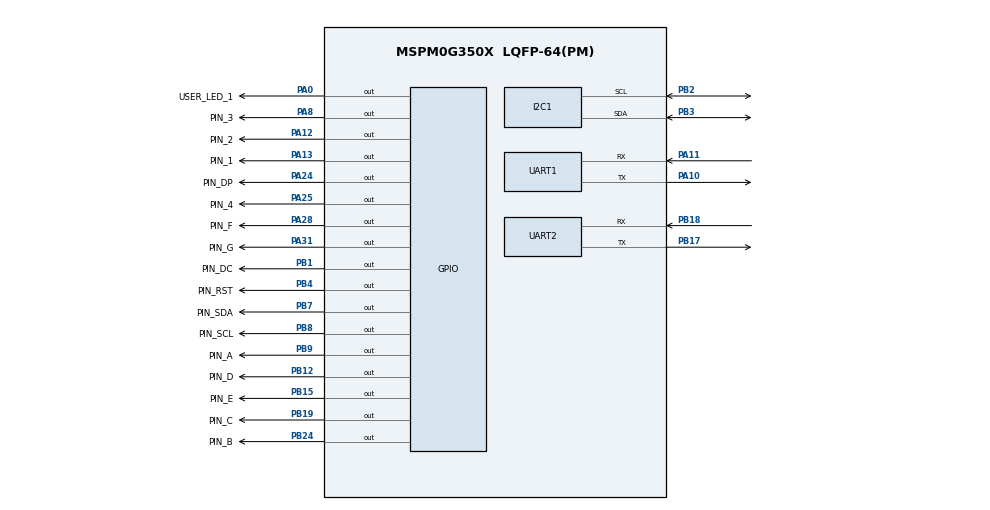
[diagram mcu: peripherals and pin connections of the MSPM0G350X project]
/**
 * @cliArgs --device "MSPM0G350X" --part "Default" --package "LQFP-64(PM)" --product "mspm0_sdk@2.05.01.00"
 * @versions {"tool":"1.24.0+4110"}
 */

/**
 * Import the modules used in this configuration.
 */
const GPIO  = scripting.addModule("/ti/driverlib/GPIO", {}, false);
const GPIO1 = GPIO.addInstance();
const GPIO2 = GPIO.addInstance();
const GPIO3 = GPIO.addInstance();
const I2C   = scripting.addModule("/ti/driverlib/I2C", {}, false);
const I2C1  = I2C.addInstance();
const UART  = scripting.addModule("/ti/driverlib/UART", {}, false);
const UART1 = UART.addInstance();
const UART2 = UART.addInstance();

/**
 * Write custom configuration values to the imported modules.
 */
GPIO1.$name                          = "GPIO_LEDS";
GPIO1.associatedPins.create(2);
GPIO1.associatedPins[0].$name        = "USER_LED_1";
GPIO1.associatedPins[0].assignedPort = "PORTA";
GPIO1.associatedPins[0].initialValue = "SET";
GPIO1.associatedPins[0].assignedPin  = "0";
GPIO1.associatedPins[0].pin.$assign  = "PA0";
GPIO1.associatedPins[1].$name        = "USER_TEST";
GPIO1.associatedPins[1].assignedPort = "PORTA";
GPIO1.associatedPins[1].assignedPin  = "15";
GPIO1.associatedPins[1].initialValue = "SET";

const Board           = scripting.addModule("/ti/driverlib/Board", {}, false);
Board.configureUnused = true;

GPIO2.$name                         = "GPIO_OLED";
GPIO2.associatedPins.create(4);
GPIO2.associatedPins[0].$name       = "PIN_SCL";
GPIO2.associatedPins[0].pin.$assign = "PB8";
GPIO2.associatedPins[1].$name       = "PIN_SDA";
GPIO2.associatedPins[1].pin.$assign = "PB7";
GPIO2.associatedPins[2].$name       = "PIN_RST";
GPIO2.associatedPins[2].pin.$assign = "PB4";
GPIO2.associatedPins[3].$name       = "PIN_DC";
GPIO2.associatedPins[3].pin.$assign = "PB1";

GPIO3.$name                          = "GPIO_GRP_0";
GPIO3.associatedPins.create(12);
GPIO3.associatedPins[0].$name        = "PIN_1";
GPIO3.associatedPins[0].pin.$assign  = "PA13";
GPIO3.associatedPins[1].$name        = "PIN_2";
GPIO3.associatedPins[1].pin.$assign  = "PA12";
GPIO3.associatedPins[2].$name        = "PIN_3";
GPIO3.associatedPins[2].pin.$assign  = "PA8";
GPIO3.associatedPins[3].$name        = "PIN_4";
GPIO3.associatedPins[3].pin.$assign  = "PA25";
GPIO3.associatedPins[4].$name        = "PIN_A";
GPIO3.associatedPins[4].pin.$assign  = "PB9";
GPIO3.associatedPins[5].$name        = "PIN_B";
GPIO3.associatedPins[5].pin.$assign  = "PB24";
GPIO3.associatedPins[6].$name        = "PIN_C";
GPIO3.associatedPins[6].pin.$assign  = "PB19";
GPIO3.associatedPins[7].$name        = "PIN_D";
GPIO3.associatedPins[7].pin.$assign  = "PB12";
GPIO3.associatedPins[8].$name        = "PIN_E";
GPIO3.associatedPins[8].pin.$assign  = "PB15";
GPIO3.associatedPins[9].$name        = "PIN_F";
GPIO3.associatedPins[9].pin.$assign  = "PA28";
GPIO3.associatedPins[10].$name       = "PIN_G";
GPIO3.associatedPins[10].pin.$assign = "PA31";
GPIO3.associatedPins[11].$name       = "PIN_DP";
GPIO3.associatedPins[11].pin.$assign = "PA24";

I2C1.basicControllerStandardBusSpeed   = "Fast";
I2C1.basicEnableController             = true;
I2C1.$name                             = "I2C_1";
I2C1.peripheral.$assign                = "I2C1";
I2C1.peripheral.sdaPin.$assign         = "PB3";
I2C1.peripheral.sclPin.$assign         = "PB2";
I2C1.sdaPinConfig.hideOutputInversion  = scripting.forceWrite(false);
I2C1.sdaPinConfig.onlyInternalResistor = scripting.forceWrite(false);
I2C1.sdaPinConfig.passedPeripheralType = scripting.forceWrite("Digital");
I2C1.sdaPinConfig.$name                = "ti_driverlib_gpio_GPIOPinGeneric4";
I2C1.sclPinConfig.hideOutputInversion  = scripting.forceWrite(false);
I2C1.sclPinConfig.onlyInternalResistor = scripting.forceWrite(false);
I2C1.sclPinConfig.passedPeripheralType = scripting.forceWrite("Digital");
I2C1.sclPinConfig.$name                = "ti_driverlib_gpio_GPIOPinGeneric5";

const SYSCTL                 = scripting.addModule("/ti/driverlib/SYSCTL", {}, false);
SYSCTL.powerPolicy           = "STANDBY0";
SYSCTL.forceDefaultClkConfig = true;
SYSCTL.clockTreeEn           = true;

UART1.$name                    = "UART_0";
UART1.rxFifoThreshold          = "DL_UART_RX_FIFO_LEVEL_ONE_ENTRY";
UART1.enableDMARX              = false;
UART1.enableDMATX              = false;
UART1.enabledInterrupts        = ["RX"];
UART1.targetBaudRate           = 115200;
UART1.peripheral.$assign       = "UART0";
UART1.peripheral.rxPin.$assign = "PA11";
UART1.peripheral.txPin.$assign = "PA10";
UART1.txPinConfig.$name        = "ti_driverlib_gpio_GPIOPinGeneric0";
UART1.rxPinConfig.$name        = "ti_driverlib_gpio_GPIOPinGeneric1";

UART2.$name                            = "UART_2";
UART2.targetBaudRate                   = 115200;
UART2.enabledInterrupts                = ["RX"];
UART2.peripheral.$assign               = "UART2";
UART2.peripheral.rxPin.$assign         = "PB18";
UART2.peripheral.txPin.$assign         = "PB17";
UART2.txPinConfig.direction            = scripting.forceWrite("OUTPUT");
UART2.txPinConfig.hideOutputInversion  = scripting.forceWrite(false);
UART2.txPinConfig.onlyInternalResistor = scripting.forceWrite(false);
UART2.txPinConfig.passedPeripheralType = scripting.forceWrite("Digital");
UART2.txPinConfig.$name                = "ti_driverlib_gpio_GPIOPinGeneric2";
UART2.rxPinConfig.hideOutputInversion  = scripting.forceWrite(false);
UART2.rxPinConfig.onlyInternalResistor = scripting.forceWrite(false);
UART2.rxPinConfig.passedPeripheralType = scripting.forceWrite("Digital");
UART2.rxPinConfig.$name                = "ti_driverlib_gpio_GPIOPinGeneric3";

/**
 * Pinmux solution for unlocked pins/peripherals. This ensures that minor changes to the automatic solver in a future
 * version of the tool will not impact the pinmux you originally saw.  These lines can be completely deleted in order to
 * re-solve from scratch.
 */
GPIO1.associatedPins[1].pin.$suggestSolution = "PA15";
Board.peripheral.$suggestSolution            = "DEBUGSS";
Board.peripheral.swclkPin.$suggestSolution   = "PA20";
Board.peripheral.swdioPin.$suggestSolution   = "PA19";
